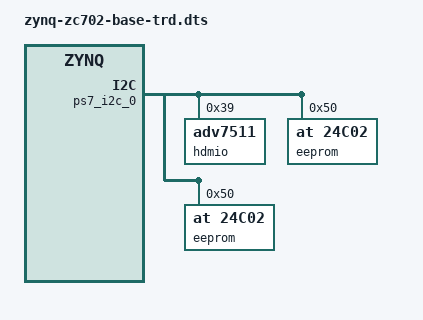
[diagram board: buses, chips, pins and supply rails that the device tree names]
/*
 * Device Tree Generator version: 1.1
 *
 * (C) Copyright 2007-2013 Xilinx, Inc.
 * (C) Copyright 2007-2013 Michal Simek
 * (C) Copyright 2007-2012 PetaLogix Qld Pty Ltd
 *
 * Michal SIMEK <monstr@monstr.eu>
 */

/include/ "zynq-zc702.dts"

/ {
	chosen {
		bootargs = "console=tty0 console=ttyPS0,115200 root=/dev/ram rw ip=192.168.1.10:::255.255.255.0:ZC702:eth0 earlyprintk mem=768M consoleblank=0";
	} ;
};

&ps7_i2c_0 {
	i2cswitch@74 {
		i2c@1 {
			#address-cells = <1>;
			#size-cells = <0>;
			reg = <1>;
			hdmio@39 {
				compatible = "adv7511";
				reg = <0x39>;
				interrupts = <0 54 4>;
				interrupt-parent = <&ps7_scugic_0>;
				dma-request = <&logicvc0>;
				edid-addr = <0x50>;
				video-input {
					input-id = <1>;
					input-style = <3>;
					input-color-depth = <8>;
					bit-justification = <1>;
					hsync-polarity = <0>;
					vsync-polarity = <0>;
					clock-delay = <3>;
				};
				video-output {
					hdmi-mode = <0>;
					output-format = <0>;
					output-color-space = <0>;
					up-conversion = <0>;
					csc-enable = <1>;
					csc-scaling-factor = <2>;
					csc-coefficients {
						a1 = <0x0B37>;
						a2 = <0x0800>;
						a3 = <0x0000>;
						a4 = <0x1A86>;
						b1 = <0x1A49>;
						b2 = <0x0800>;
						b3 = <0x1D3F>;
						b4 = <0x0422>;
						c1 = <0x0000>;
						c2 = <0x0800>;
						c3 = <0x0E2D>;
						c4 = <0x1914>;
					};
				};
			};
		};
		i2c@5{
			#address-cells = <1>;
			#size-cells = <0>;
			reg = <5>;
			eeprom@50 {
				compatible = "at,24c02";
				reg = <0x50>;
			};
		};
		i2c@6{
			#address-cells = <1>;
			#size-cells = <0>;
			reg = <6>;
			eeprom@50 {
				compatible = "at,24c02";
				reg = <0x50>;
			};
		};
	};
} ;

&ps7_axi_interconnect_0 {
	axi_sobel_0: axi-sobel@0x400D0000 {
		compatible = "generic-uio";
		reg = <0x400D0000 0x10000>;
		interrupts = <0 55 4>;
		interrupt-parent = <&ps7_scugic_0>;
	};
	yuv2rgb_0: v-ycrcb2rgb@0x40050000 {
		compatible = "generic-uio";
		reg = <0x40050000 0x10000>;
	};
	tpg_0: v-tpg@40080000 {
		compatible = "generic-uio";
		reg = <0x40080000 0x10000>;
	};
	cresample_0: v-cresample@40040000 {
		compatible = "generic-uio";
		reg = <0x40040000 0x10000>;
	};
	vtc_0: v-tc@40070000 {
		compatible = "generic-uio";
		reg = <0x40070000 0x10000>;
	};
	perf_mon_hp0_hp2: axi-perf-mon@400f0000 {
		compatible = "generic-uio";
		reg = <0x400f0000 0x10000>;
	};
	axi_vdma_0: axivdma@0x40090000 {
		#address-cells = <1>;
		#size-cells = <1>;
		compatible = "xlnx,axi-vdma";
		ranges = <0x40090000 0x40090000 0x10000>;
		reg = <0x40090000 0x10000>;
		xlnx,flush-fsync = <0x1>;
		xlnx,num-fstores = <0x3>;
		xlnx,family = "zynq-770";
		dma-channel@0x40090000 {
			compatible = "xlnx,axi-vdma-s2mm-channel";
			interrupt-parent = <&ps7_scugic_0>;
			interrupts = <0 58 4>;
			xlnx,datawidth = <0x08>;
			xlnx,genlock-mode = <0x1>;
			xlnx,include-dre = <0x1>;
			xlnx,device-id = <0x0>;
		};
	};
	axi_vdma_1: axivdma@0x400B0000 {
		#address-cells = <1>;
		#size-cells = <1>;
		compatible = "xlnx,axi-vdma";
		ranges = <0x400B0000 0x400B0000 0x10000>;
		reg = <0x400B0000 0x10000>;
		xlnx,flush-fsync = <0x1>;
		xlnx,num-fstores = <0x3>;
		xlnx,family = "zynq-770";
		dma-s2mmchannel@0x400B0000 {
			compatible = "xlnx,axi-vdma-s2mm-channel";
			interrupt-parent = <&ps7_scugic_0>;
			interrupts = <0 57 4>;
			xlnx,datawidth = <0x08>;
			xlnx,genlock-mode = <0x1>;
			xlnx,include-dre = <0x1>;
			xlnx,device-id = <0x1>;
		};
		dma-mm2schannel@0x400B0000 {
			compatible = "xlnx,axi-vdma-mm2s-channel";
			interrupt-parent = <&ps7_scugic_0>;
			interrupts = <0 56 4>;
			xlnx,datawidth = <0x08>;
			xlnx,genlock-mode = <0x1>;
			xlnx,include-dre = <0x1>;
			xlnx,device-id = <0x1>;
		};
	};
	logicvc0: logicvc@40030000 {
		compatible = "xylon,logicvc-3.00.a";
		reg = <0x40030000 0x6000>;
		interrupt-parent = <&ps7_scugic_0>;
		interrupts = <0 59 4>;
		xlnx,display-interface = <0>;
		xlnx,display-color-space = <1>;
		xlnx,ip-license-type = <0>;
		xlnx,ip-major-revision = <3>;
		xlnx,ip-minor-revision = <0>;
		xlnx,ip-patch-level = <0>;
		xlnx,num-of-layers = <3>;
		xlnx,layer-0-type = <0>;
		xlnx,layer-0-alpha-mode = <0>;
		xlnx,layer-0-data-width = <16>;
		xlnx,layer-0-offset = <0>;
		xlnx,layer-1-type = <0>;
		xlnx,layer-1-alpha-mode = <0>;
		xlnx,layer-1-data-width = <24>;
		xlnx,layer-1-offset = <1620>;
		xlnx,layer-2-type = <0>;
		xlnx,layer-2-alpha-mode = <0>;
		xlnx,layer-2-data-width = <24>;
		xlnx,layer-2-offset = <6480>;
		xlnx,layer-3-type = <0>;
		xlnx,layer-3-alpha-mode = <0>;
		xlnx,layer-3-data-width = <24>;
		xlnx,layer-3-offset = <9720>;
		xlnx,layer-4-type = <0>;
		xlnx,layer-4-alpha-mode = <0>;
		xlnx,layer-4-data-width = <24>;
		xlnx,layer-4-offset = <12960>;
		xlnx,buffer-0-offset = <1080>;
		xlnx,buffer-1-offset = <1080>;
		xlnx,buffer-2-offset = <1080>;
		xlnx,buffer-3-offset = <1080>;
		xlnx,buffer-4-offset = <1080>;
		xlnx,little-endian = <1>;
		xlnx,readable-regs = <1>;
		xlnx,row-stride = <2048>;
		xlnx,use-background = <1>;
		xlnx,use-size-position = <1>;
		xlnx,vmem-baseaddr = <0x30000000>;
		xlnx,vmem-highaddr = <0x3FFFFFFF>;

		//0-EXT; 1-ZynqPS; 2-logiCLK; 3-SI570
		pixel-clock-source = <3>;
		pixel-data-invert = <0>;
		pixel-clock-active-high = <1>;
		pixel-component-format = "ARGB";
		pixel-component-layer = <0>,<1>,<2>;
		active-layer = <0>;
		videomode = "1920x1080";
		edid {
			preffered-videomode = <1>;
			display-data = <0>;
		};
	};
	xylon-video-params {
		800x480_TM050RBH01 {
			name = "800x480_TM050RBH01";
			refresh = <60>;
			xres = <800>;
			yres = <480>;
			pixclock-khz = <30000>;
			left-margin = <40>;
			right-margin = <40>;
			upper-margin = <29>;
			lower-margin = <13>;
			hsync-len = <48>;
			vsync-len = <3>;
			sync = <0>;
			vmode = <0>;
		};
		1280x720 {
			name = "1280x720";
			refresh = <60>;
			xres = <1280>;
			yres = <720>;
			pixclock-khz = <74250>;
			left-margin = <220>;
			right-margin = <110>;
			upper-margin = <20>;
			lower-margin = <5>;
			hsync-len = <40>;
			vsync-len = <5>;
			sync = <0>;
			vmode = <0>;
		};
		1680x1050 {
			name = "1680x1050";
			refresh = <60>;
			xres = <1680>;
			yres = <1050>;
			pixclock-khz = <119000>;
			left-margin = <80>;
			right-margin = <48>;
			upper-margin = <21>;
			lower-margin = <3>;
			hsync-len = <32>;
			vsync-len = <6>;
			sync = <0>;
			vmode = <0>;
		};
		1920x1080 {
			name = "1920x1080";
			refresh = <60>;
			xres = <1920>;
			yres = <1080>;
			pixclock-khz = <148500>;
			left-margin = <148>;
			right-margin = <88>;
			upper-margin = <36>;
			lower-margin = <4>;
			hsync-len = <44>;
			vsync-len = <5>;
			sync = <0>;
			vmode = <0>;
		};
	};
} ;
